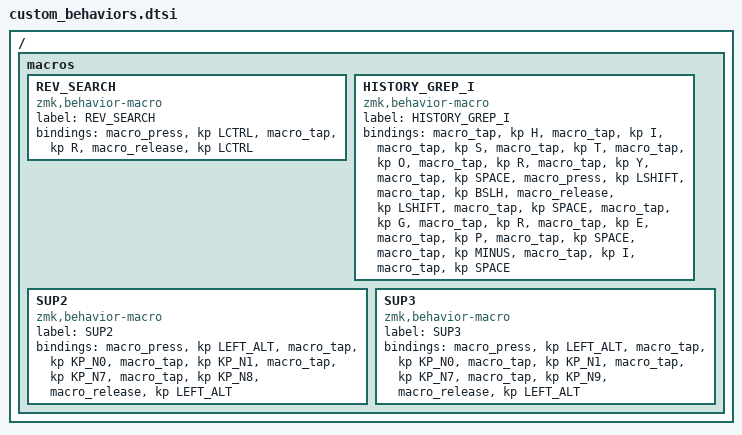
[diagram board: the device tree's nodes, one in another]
/*
 * Custom behaviors / macros
 * - Reverse search for Linux terminal (Ctrl + R)
 * - history | grep -i
 */

 / {
    macros {
        // =========================
        // Ctrl + R  (reverse search)
        // =========================
        REV_SEARCH: REV_SEARCH {
            compatible = "zmk,behavior-macro";
            #binding-cells = <0>;
            label = "REV_SEARCH";
            bindings =
                <&macro_press   &kp LCTRL>,
                <&macro_tap     &kp R>,
                <&macro_release &kp LCTRL>;
        };

        // =========================
        // history | grep -i␠
        // (tutto minuscolo, spazio finale)
        // =========================
        HISTORY_GREP_I: HISTORY_GREP_I {
            compatible = "zmk,behavior-macro";
            #binding-cells = <0>;
            label = "HISTORY_GREP_I";
            bindings =
                <&macro_tap &kp H>,
                <&macro_tap &kp I>,
                <&macro_tap &kp S>,
                <&macro_tap &kp T>,
                <&macro_tap &kp O>,
                <&macro_tap &kp R>,
                <&macro_tap &kp Y>,
                <&macro_tap &kp SPACE>,
                <&macro_press &kp LSHIFT>,
                <&macro_tap   &kp BSLH>,
                <&macro_release &kp LSHIFT>,
                <&macro_tap &kp SPACE>,
                <&macro_tap &kp G>,
                <&macro_tap &kp R>,
                <&macro_tap &kp E>,
                <&macro_tap &kp P>,
                <&macro_tap &kp SPACE>,
                <&macro_tap &kp MINUS>,
                <&macro_tap &kp I>,
                <&macro_tap &kp SPACE>;
        };

        // =========================
        // Windows Alt codes: superscript 2 and 3
        // =========================
        SUP2: SUP2 {
            compatible = "zmk,behavior-macro";
            #binding-cells = <0>;
            label = "SUP2";
            bindings =
                <&macro_press &kp LEFT_ALT>,
                <&macro_tap &kp KP_N0>,
                <&macro_tap &kp KP_N1>,
                <&macro_tap &kp KP_N7>,
                <&macro_tap &kp KP_N8>,
                <&macro_release &kp LEFT_ALT>;
        };

        SUP3: SUP3 {
            compatible = "zmk,behavior-macro";
            #binding-cells = <0>;
            label = "SUP3";
            bindings =
                <&macro_press &kp LEFT_ALT>,
                <&macro_tap &kp KP_N0>,
                <&macro_tap &kp KP_N1>,
                <&macro_tap &kp KP_N7>,
                <&macro_tap &kp KP_N9>,
                <&macro_release &kp LEFT_ALT>;
        };
    };
};
